# ESP32-S31 register map
Vendor: ESPRESSIF SYSTEMS (SHANGHAI) CO., LTD.; Series: ESP32 S-Series; File version: 1
CPU: RV32IMAFC r0p0, little endian, no MPU, FPU, 0 interrupt priority bits
Address unit: 32 bits
Registers are 32-bit, read-write, reset 0x0 unless marked. A register's access mark holds for its fields unless they carry their own. Offsets are from the block's base; [hi:lo] are bit positions; {n}, {i} and the like mark numbered series.

## LP_SPI — LP SPI Controller
Base 0x20812000
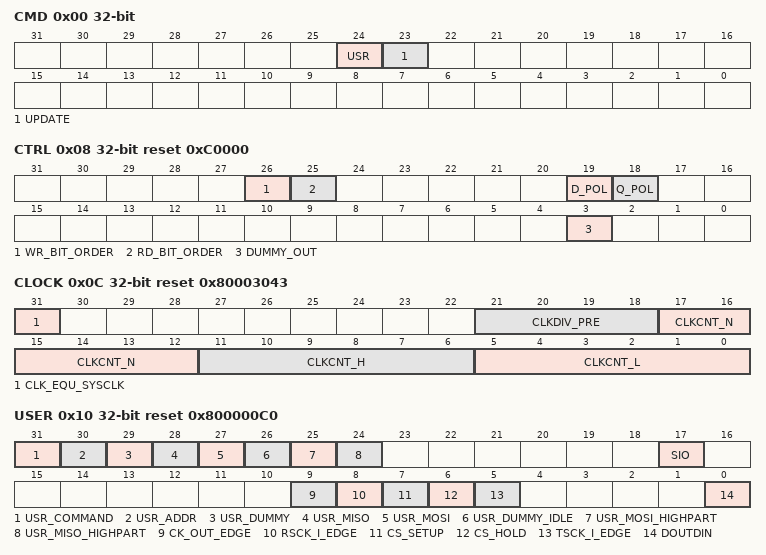
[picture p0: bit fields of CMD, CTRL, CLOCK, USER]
0x00 CMD access per field
  [24] USR rw, [23] UPDATE wo
0x04 ADDR
  [31:0] USR_ADDR_VALUE
0x08 CTRL reset 0xC0000
  [26] WR_BIT_ORDER, [25] RD_BIT_ORDER, [19] D_POL, [18] Q_POL, [3] DUMMY_OUT
0x0C CLOCK reset 0x80003043
  [31] CLK_EQU_SYSCLK, [21:18] CLKDIV_PRE, [17:12] CLKCNT_N, [11:6] CLKCNT_H, [5:0] CLKCNT_L
0x10 USER reset 0x800000C0
  [31] USR_COMMAND, [30] USR_ADDR, [29] USR_DUMMY, [28] USR_MISO, [27] USR_MOSI, [26] USR_DUMMY_IDLE, [25] USR_MOSI_HIGHPART, [24] USR_MISO_HIGHPART, [17] SIO, [9] CK_OUT_EDGE, [8] RSCK_I_EDGE, [7] CS_SETUP, [6] CS_HOLD, [5] TSCK_I_EDGE, [0] DOUTDIN
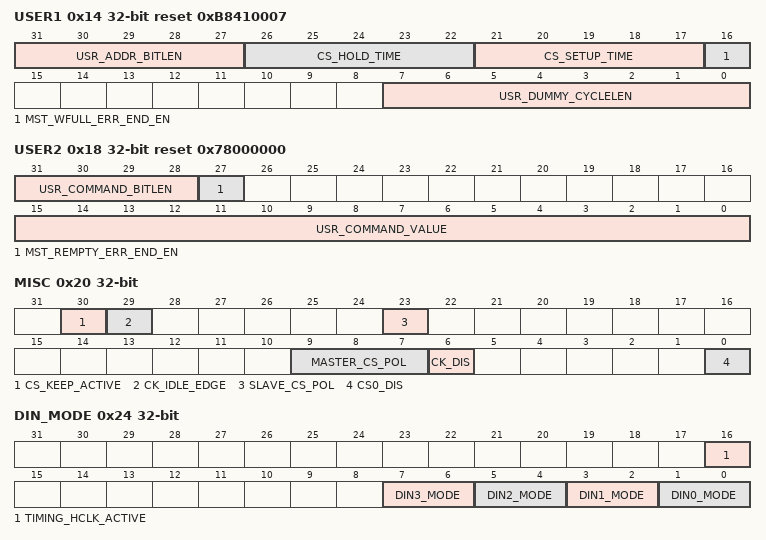
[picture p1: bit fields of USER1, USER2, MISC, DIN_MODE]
0x14 USER1 reset 0xB8410007
  [31:27] USR_ADDR_BITLEN, [26:22] CS_HOLD_TIME, [21:17] CS_SETUP_TIME, [16] MST_WFULL_ERR_END_EN, [7:0] USR_DUMMY_CYCLELEN
0x18 USER2 reset 0x78000000
  [31:28] USR_COMMAND_BITLEN, [27] MST_REMPTY_ERR_END_EN, [15:0] USR_COMMAND_VALUE
0x1C MS_DLEN
  [17:0] MS_DATA_BITLEN
0x20 MISC
  [30] CS_KEEP_ACTIVE, [29] CK_IDLE_EDGE, [23] SLAVE_CS_POL, [9:7] MASTER_CS_POL, [6] CK_DIS, [0] CS0_DIS
0x24 DIN_MODE
  [16] TIMING_HCLK_ACTIVE, [2n+1:2n] DIN{n}_MODE (n=0..3)
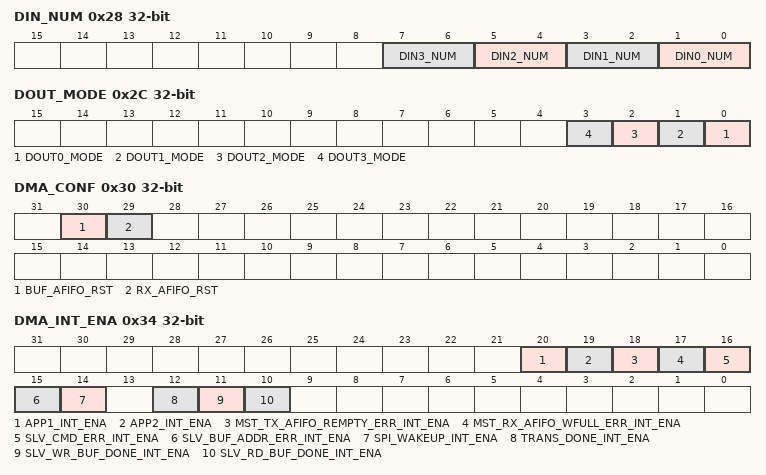
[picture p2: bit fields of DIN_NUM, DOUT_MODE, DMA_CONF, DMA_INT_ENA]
0x28 DIN_NUM
  [2n+1:2n] DIN{n}_NUM (n=0..3)
0x2C DOUT_MODE
  [n] DOUT{n}_MODE (n=0..3)
0x30 DMA_CONF wo
  [30] BUF_AFIFO_RST, [29] RX_AFIFO_RST
0x34 DMA_INT_ENA
  [20] APP1_INT_ENA, [19] APP2_INT_ENA, [18] MST_TX_AFIFO_REMPTY_ERR_INT_ENA, [17] MST_RX_AFIFO_WFULL_ERR_INT_ENA, [16] SLV_CMD_ERR_INT_ENA, [15] SLV_BUF_ADDR_ERR_INT_ENA, [14] SPI_WAKEUP_INT_ENA, [12] TRANS_DONE_INT_ENA, [11] SLV_WR_BUF_DONE_INT_ENA, [10] SLV_RD_BUF_DONE_INT_ENA
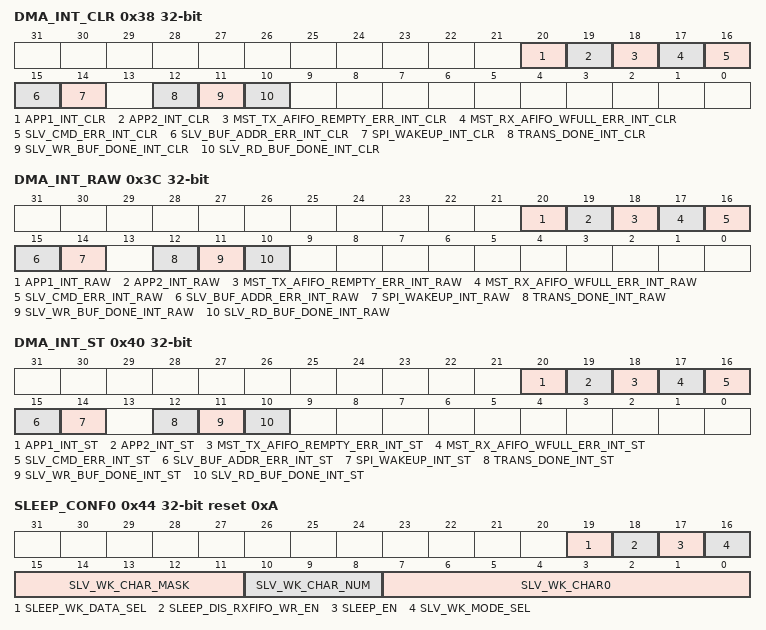
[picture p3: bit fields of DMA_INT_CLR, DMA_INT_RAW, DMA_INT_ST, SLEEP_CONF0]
0x38 DMA_INT_CLR wo
  [20] APP1_INT_CLR, [19] APP2_INT_CLR, [18] MST_TX_AFIFO_REMPTY_ERR_INT_CLR, [17] MST_RX_AFIFO_WFULL_ERR_INT_CLR, [16] SLV_CMD_ERR_INT_CLR, [15] SLV_BUF_ADDR_ERR_INT_CLR, [14] SPI_WAKEUP_INT_CLR, [12] TRANS_DONE_INT_CLR, [11] SLV_WR_BUF_DONE_INT_CLR, [10] SLV_RD_BUF_DONE_INT_CLR
0x3C DMA_INT_RAW
  [20] APP1_INT_RAW, [19] APP2_INT_RAW, [18] MST_TX_AFIFO_REMPTY_ERR_INT_RAW, [17] MST_RX_AFIFO_WFULL_ERR_INT_RAW, [16] SLV_CMD_ERR_INT_RAW, [15] SLV_BUF_ADDR_ERR_INT_RAW, [14] SPI_WAKEUP_INT_RAW, [12] TRANS_DONE_INT_RAW, [11] SLV_WR_BUF_DONE_INT_RAW, [10] SLV_RD_BUF_DONE_INT_RAW
0x40 DMA_INT_ST ro
  [20] APP1_INT_ST, [19] APP2_INT_ST, [18] MST_TX_AFIFO_REMPTY_ERR_INT_ST, [17] MST_RX_AFIFO_WFULL_ERR_INT_ST, [16] SLV_CMD_ERR_INT_ST, [15] SLV_BUF_ADDR_ERR_INT_ST, [14] SPI_WAKEUP_INT_ST, [12] TRANS_DONE_INT_ST, [11] SLV_WR_BUF_DONE_INT_ST, [10] SLV_RD_BUF_DONE_INT_ST
0x44 SLEEP_CONF0 reset 0xA
  [19] SLEEP_WK_DATA_SEL, [18] SLEEP_DIS_RXFIFO_WR_EN, [17] SLEEP_EN, [16] SLV_WK_MODE_SEL, [15:11] SLV_WK_CHAR_MASK, [10:8] SLV_WK_CHAR_NUM, [7:0] SLV_WK_CHAR0
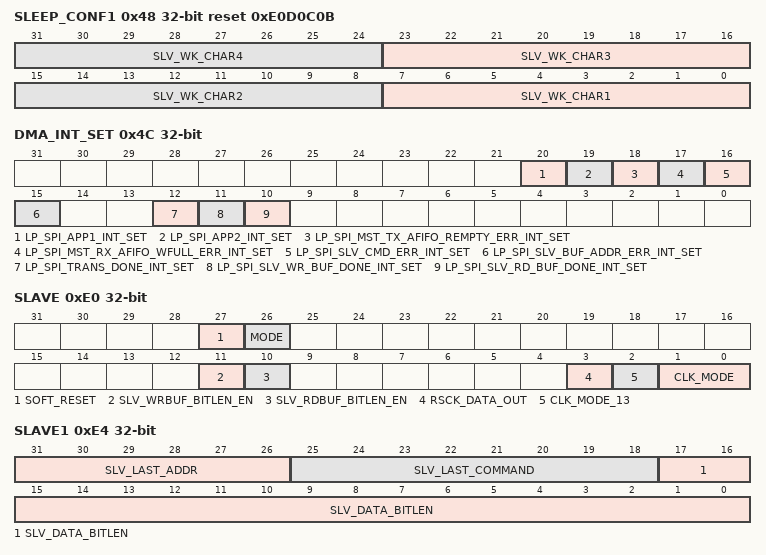
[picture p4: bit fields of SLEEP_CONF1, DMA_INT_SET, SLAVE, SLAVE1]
0x48 SLEEP_CONF1 reset 0xE0D0C0B
  [8n-1:8n-8] SLV_WK_CHAR{n} (n=1..4)
0x4C DMA_INT_SET wo
  [20] LP_SPI_APP1_INT_SET, [19] LP_SPI_APP2_INT_SET, [18] LP_SPI_MST_TX_AFIFO_REMPTY_ERR_INT_SET, [17] LP_SPI_MST_RX_AFIFO_WFULL_ERR_INT_SET, [16] LP_SPI_SLV_CMD_ERR_INT_SET, [15] LP_SPI_SLV_BUF_ADDR_ERR_INT_SET, [12] LP_SPI_TRANS_DONE_INT_SET, [11] LP_SPI_SLV_WR_BUF_DONE_INT_SET, [10] LP_SPI_SLV_RD_BUF_DONE_INT_SET
{0x98+4i} W{i} (i=0..15)
  [31:0] BUF0
0xE0 SLAVE access per field
  [27] SOFT_RESET wo, [26] MODE rw, [11] SLV_WRBUF_BITLEN_EN rw, [10] SLV_RDBUF_BITLEN_EN rw, [3] RSCK_DATA_OUT rw, [2] CLK_MODE_13 rw, [1:0] CLK_MODE rw
0xE4 SLAVE1
  [31:26] SLV_LAST_ADDR, [25:18] SLV_LAST_COMMAND, [17:0] SLV_DATA_BITLEN
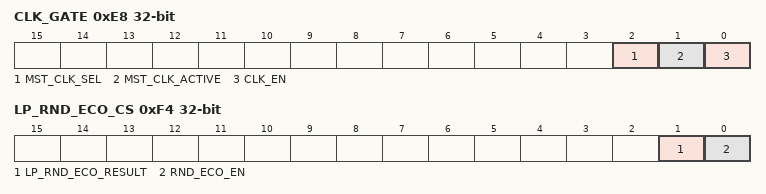
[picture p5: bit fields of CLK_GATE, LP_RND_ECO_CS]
0xE8 CLK_GATE
  [2] MST_CLK_SEL, [1] MST_CLK_ACTIVE, [0] CLK_EN
0xF0 DATE reset 0x2009040
  [27:0] DATE
0xF4 LP_RND_ECO_CS access per field
  [1] LP_RND_ECO_RESULT ro, [0] RND_ECO_EN rw
0xF8 LP_RND_ECO_LOW
  [31:0] RND_ECO_LOW
0xFC LP_RND_ECO_HIGH reset 0xFFFF
  [31:0] RND_ECO_HIGH
